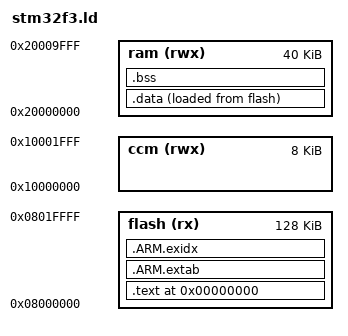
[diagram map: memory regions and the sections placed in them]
/* Linker script for STM32F303 Cortex-M3 ARM MCU */

/* Define the memory mapping of the chip */
MEMORY
{
  flash (rx)  : ORIGIN = 0x08000000, LENGTH = 128K
  ram (rwx) : ORIGIN = 0x20000000, LENGTH = 40K
  ccm (rwx) : ORIGIN = 0x10000000, LENGTH = 8K
}

/* Define some useful symbols that can be used from the code */
__rom_start__	= ORIGIN(flash);
__rom_size__	= LENGTH(flash);
__ram_start__	= ORIGIN(ram);
__ram_size__	= LENGTH(ram);
__ram_end__	= __ram_start__ + __ram_size__;
__ccm_start__	= ORIGIN(ccm);
__ccm_size__	= LENGTH(ccm);

/* These are used to setup the C heap and stack */
/* The stack is at the top of RAM and grows downwards, it takes half the memory */
__stack_end__	= __ram_end__;		/* Top of RAM */

/* The heap is the remaining space in RAM when all the statics and the stacks are allocated.
 * It only gets used if you use malloc()/free(), anyway. */
__heap_start__	= __bss_end__;		/* Between bss and stack */

/* Now define the memory mapping. The section names in parentheses reflect the
 * sections generated by the compiler. The * means 'from all object files'. The
 * only case where you need to do otherwise is usually to setup the interrupt
 * vectors, if you need them at the start of flash or some other useful place.*/
SECTIONS
{
  . = 0;

	/* Here is the ROM */
  .text : {
  KEEP(*(.boot*))				/* Reset vectors */
  *(.text*)				/* Program code */
  *(.rodata*)			/* Read only data */
  *(.glue_7)
  *(.glue_7t)
  *(.eh_frame)
  . = ALIGN(4);
  __ctors_start__ = .;
  KEEP(*(.init_array));			/* C++ constructors */
  KEEP(*(.ctors));			/* C++ constructors */
  __ctors_end__ = .;
  . = ALIGN(16);
  __text_end__ = .;
  } >flash

  /* Initialized data is allocated in flash, but will be moved to RAM by the
   * boot code. */
  .data : ALIGN(16) {
  __data_beg__ = .;			/* Used in crt0.S */
  *(.data)				/* Initialized data */
  __data_end__ = .;			/* Used in crt0.S */
  } >ram AT > flash 

  /* And here is all the uninitialized data. It will follow the initialized
   * part in RAM, and need not be copied from flash, only zero-cleared. */
  .bss (NOLOAD) : ALIGN(16) {
  __bss_beg__ = .;			/* Used in crt0.S */
  *(.bss)				/* Uninitialized data */
  *(COMMON)				/* Common data */
  __bss_end__ = .;			/* Used in crt0.S */
  } >ram

/* C++ exception unwinding stuff--needed by some toolchains */

  .ARM.extab : { *(.ARM.extab* .gnu.linkonce.armextab.*) } >flash

  __exidx_start = .;
  .ARM.exidx : { *(.ARM.exidx* .gnu.linkonce.armexidx.*) } >flash
  __exidx_end = .;
}  
